# STM32G0B0 register map
File version: 1.6
CPU: CM0 r0p1, little endian, MPU, no FPU, 2 interrupt priority bits
Registers are 32-bit, read-write, reset 0x0 unless marked. A register's access mark holds for its fields unless they carry their own. Offsets are from the block's base; [hi:lo] are bit positions; {n}, {i} and the like mark numbered series.

## PWR — Power control
Base 0x40007000
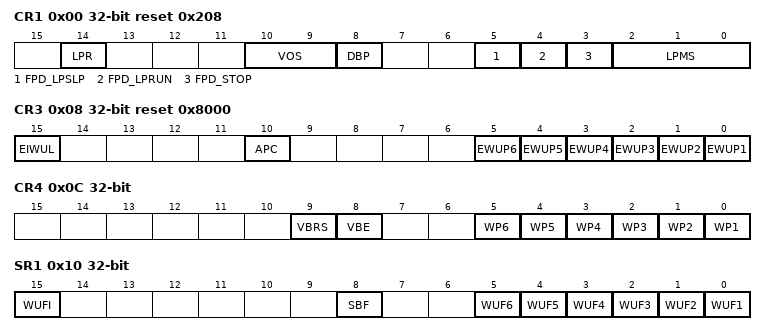
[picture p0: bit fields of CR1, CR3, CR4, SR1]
0x00 CR1 reset 0x208 — Power control register 1
  [14] LPR — Low-power run
  [10:9] VOS — Voltage scaling range selection
  [8] DBP — Disable backup domain write protection
  [5] FPD_LPSLP — Flash memory powered down during Low-power sleep mode
  [4] FPD_LPRUN — Flash memory powered down during Low-power run mode
  [3] FPD_STOP — Flash memory powered down during Stop mode
  [2:0] LPMS — Low-power mode selection
0x04 CR2 — Power control register 2
  [10] USV
0x08 CR3 reset 0x8000 — Power control register 3
  [15] EIWUL — Enable internal wakeup line
  [10] APC — Apply pull-up and pull-down configuration
  [5] EWUP6 — Enable WKUP6 wakeup pin
  [4] EWUP5 — Enable WKUP5 wakeup pin
  [n-1] EWUP{n} (n=1..4) — Enable Wakeup pin WKUP{n}
0x0C CR4 — Power control register 4
  [9] VBRS — VBAT battery charging resistor selection
  [8] VBE — VBAT battery charging enable
  [5] WP6 — WKUP6 wakeup pin polarity
  [n-1] WP{n} (n=1..5) — Wakeup pin WKUP{n} polarity
0x10 SR1 ro — Power status register 1
  [15] WUFI — Wakeup flag internal
  [8] SBF — Standby flag
  [n-1] WUF{n} (n=1..6) — Wakeup flag {n}
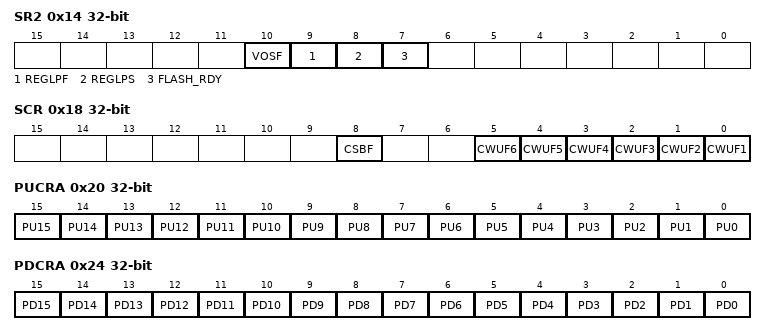
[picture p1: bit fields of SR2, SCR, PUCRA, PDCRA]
0x14 SR2 ro — Power status register 2
  [10] VOSF — Voltage scaling flag
  [9] REGLPF — Low-power regulator flag
  [8] REGLPS — Low-power regulator started
  [7] FLASH_RDY — Flash ready flag
0x18 SCR wo — Power status clear register
  [8] CSBF — Clear standby flag
  [n-1] CWUF{n} (n=1..6) — Clear wakeup flag {n}
0x20 PUCRA — Power Port A pull-up control register
  [n] PU{n} (n=0..15) — Port A pull-up bit y (y=0..15)
0x24 PDCRA — Power Port A pull-down control register
  [n] PD{n} (n=0..15) — Port A pull-down bit y (y=0..15)
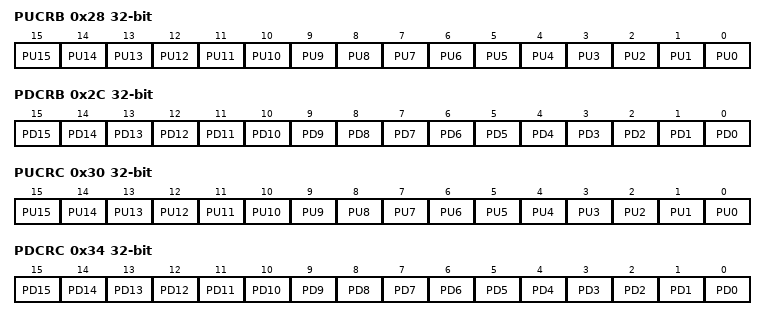
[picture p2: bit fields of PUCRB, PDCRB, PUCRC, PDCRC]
0x28 PUCRB — Power Port B pull-up control register
  [n] PU{n} (n=0..15) — Port B pull-up bit y (y=0..15)
0x2C PDCRB — Power Port B pull-down control register
  [n] PD{n} (n=0..15) — Port B pull-down bit y (y=0..15)
0x30 PUCRC — Power Port C pull-up control register
  [n] PU{n} (n=0..15) — Port C pull-up bit y (y=0..15)
0x34 PDCRC — Power Port C pull-down control register
  [n] PD{n} (n=0..15) — Port C pull-down bit y (y=0..15)
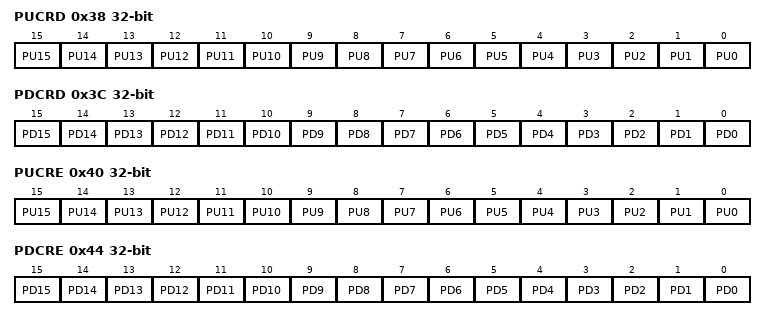
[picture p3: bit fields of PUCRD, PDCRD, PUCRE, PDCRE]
0x38 PUCRD — Power Port D pull-up control register
  [n] PU{n} (n=0..15) — Port D pull-up bit y (y=0..15)
0x3C PDCRD — Power Port D pull-down control register
  [n] PD{n} (n=0..15) — Port D pull-down bit y (y=0..15)
0x40 PUCRE — Power Port E pull-UP control register
  [n] PU{n} (n=0..15) — Port E pull-up bit y (y=0..15)
0x44 PDCRE — Power Port E pull-down control register
  [n] PD{n} (n=0..15) — Port E pull-down bit y (y=0..15)
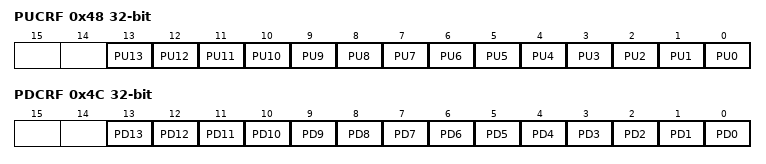
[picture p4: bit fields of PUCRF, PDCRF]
0x48 PUCRF — Power Port F pull-up control register
  [n] PU{n} (n=0..13) — Port F pull-up bit y (y=0..15)
0x4C PDCRF — Power Port F pull-down control register
  [n] PD{n} (n=0..13) — Port F pull-down bit y (y=0..15)

## TIM6 — Basic timers
Base 0x40001000
Same registers: TIM7 0x40001400
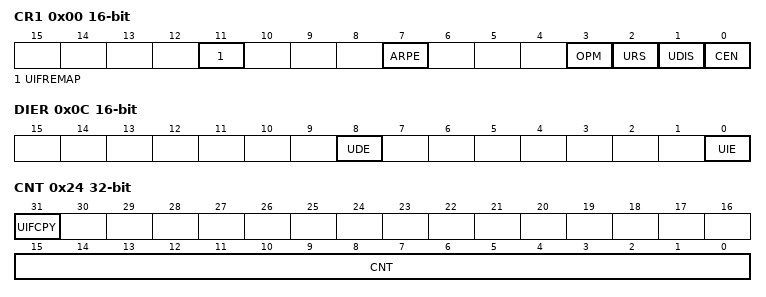
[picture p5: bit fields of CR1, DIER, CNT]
0x00 CR1 16-bit — control register 1
  [11] UIFREMAP — UIF status bit remapping
  [7] ARPE — Auto-reload preload enable
    0=Disabled (TIMx_APRR register is not buffered); 1=Enabled (TIMx_APRR register is buffered)
  [3] OPM — One-pulse mode
    0=Disabled (Counter is not stopped at update event); 1=Enabled (Counter stops counting at the next update event (clearing the CEN bit))
  [2] URS — Update request source This bit is set and cleared by software to select the UEV event sources. Counter overflow/underflow Setting the UG bit Update generation through the slave mode controller
    0=AnyEvent (Any of counter overflow/underflow, setting UG, or update through slave mode, generates an update interrupt or DMA request); 1=CounterOnly (Only counter overflow/underflow generates an update interrupt or DMA request)
  [1] UDIS — Update disable This bit is set and cleared by software to enable/disable UEV event generation. Counter overflow/underflow Setting the UG bit Update generation through the slave mode controller Buffered registers are then loaded with their preload values.
    0=Enabled (Update event enabled); 1=Disabled (Update event disabled)
  [0] CEN — Counter enable Note: Gated mode can work only if the CEN bit has been previously set by software. However trigger mode can set the CEN bit automatically by hardware. CEN is cleared automatically in one-pulse mode, when an update event occurs.
    0=Disabled (Counter disabled); 1=Enabled (Counter enabled)
0x04 CR2 16-bit — control register 2
  [6:4] MMS — Master mode selection These bits are used to select the information to be sent in master mode to slave timers for synchronization (TRGO). The combination is as follows: When the Counter Enable signal is controlled by the trigger input, there is a delay on TRGO, except if the master/slave mode is selected (see the MSM bit description in the TIMx_SMCR register). Note: The clock of the slave timer or ADC must be enabled prior to receive events from the master timer, and must not be changed on-the-fly while triggers are received from the master timer.
    0=Reset (Use UG bit from TIMx_EGR register); 1=Enable (Use CNT bit from TIMx_CEN register); 2=Update (Use the update event)
0x0C DIER 16-bit — DMA/Interrupt enable register
  [8] UDE — Update DMA request enable
    0=Disabled (Update DMA request disabled); 1=Enabled (Update DMA request enabled)
  [0] UIE — Update interrupt enable
    0=Disabled (Update interrupt disabled); 1=Enabled (Update interrupt enabled)
0x10 SR 16-bit — status register
  [0] UIF write-0-clears — Update interrupt flag
    on read: 0=NoUpdateOccurred; 1=UpdatePending (Update interrupt pending) | on write: 0=Clear flag
0x14 EGR wo — event generation register
  [0] UG — Update generation This bit can be set by software, it is automatically cleared by hardware.
    1=Update (Re-initializes the timer counter and generates an update of the registers.)
0x24 CNT — counter
  [31] UIFCPY ro — UIF Copy This bit is a read-only copy of the UIF bit of the TIMx_ISR register. If the UIFREMAP bit in TIMx_CR1 is reset, bit 31 is reserved and read as 0.
  [15:0] CNT — Counter value
0x24 CNT16 16-bit (alternate view of CNT) — 16-bit counter register
  [15:0] CNT — counter value
0x28 PSC 16-bit — prescaler
  [15:0] PSC — Prescaler value
0x2C ARR 16-bit reset 0xFFFF — auto-reload register
  [15:0] ARR — Prescaler value

## VREFBUF — System configuration controller
Base 0x40010030
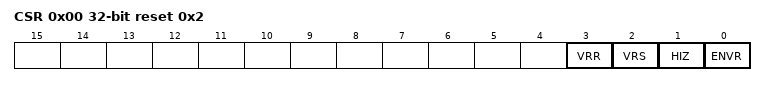
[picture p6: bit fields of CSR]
0x00 CSR access per field reset 0x2 — VREFBUF control and status register
  [3] VRR ro — Voltage reference buffer ready
  [2] VRS rw — Voltage reference scale This bit selects the value generated by the voltage reference buffer.
  [1] HIZ rw — High impedance mode This bit controls the analog switch to connect or not the VREF+ pin. Refer to for the mode descriptions depending on ENVR bit configuration.
  [0] ENVR rw — Voltage reference buffer mode enable This bit is used to enable the voltage reference buffer mode.
0x04 CCR — VREFBUF calibration control register
  [5:0] TRIM — Trimming code These bits are automatically initialized after reset with the trimming value stored in the Flash memory during the production test. Writing into these bits allows the tuning of the internal reference buffer voltage.

## WWDG — System window watchdog
Base 0x40002C00
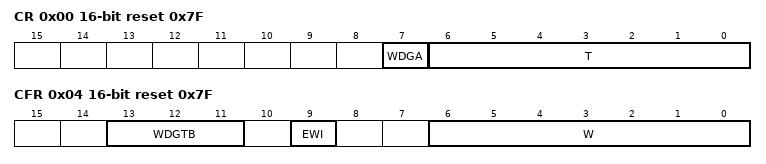
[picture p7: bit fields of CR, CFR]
0x00 CR 16-bit reset 0x7F — Control register
  [7] WDGA — Activation bit This bit is set by software and only cleared by hardware after a reset. When WDGA=1, the watchdog can generate a reset.
    0=Disabled (Watchdog disabled); 1=Enabled (Watchdog enabled)
  [6:0] T — 7-bit counter (MSB to LSB) These bits contain the value of the watchdog counter, decremented every (4096 x 2WDGTB[1:0]) PCLK cycles. A reset is produced when it is decremented from 0x40 to 0x3F (T6 becomes cleared).
0x04 CFR 16-bit reset 0x7F — Configuration register
  [13:11] WDGTB — Timer base The timebase of the prescaler can be modified as follows:
    0=Div1 (Counter clock (PCLK1 div 4096) div 1); 1=Div2 (Counter clock (PCLK1 div 4096) div 2); 2=Div4 (Counter clock (PCLK1 div 4096) div 4); 3=Div8 (Counter clock (PCLK1 div 4096) div 8); 4=Div16 (Counter clock (PCLK1 div 4096) div 16); 5=Div32 (Counter clock (PCLK1 div 4096) div 32); 6=Div64 (Counter clock (PCLK1 div 4096) div 64); 7=Div128 (Counter clock (PCLK1 div 4096) div 128)
  [9] EWI — Early wakeup interrupt When set, an interrupt occurs whenever the counter reaches the value 0x40. This interrupt is only cleared by hardware after a reset.
    on write: 1=Enable (interrupt occurs whenever the counter reaches the value 0x40)
  [6:0] W — 7-bit window value These bits contain the window value to be compared with the down-counter.
0x08 SR 16-bit — Status register
  [0] EWIF write-0-clears — Early wakeup interrupt flag
    on read: 0=Finished (The EWI Interrupt Service Routine has been serviced); 1=Pending (The EWI Interrupt Service Routine has been triggered) | on write: 0=Finished (The EWI Interrupt Service Routine has been serviced)
